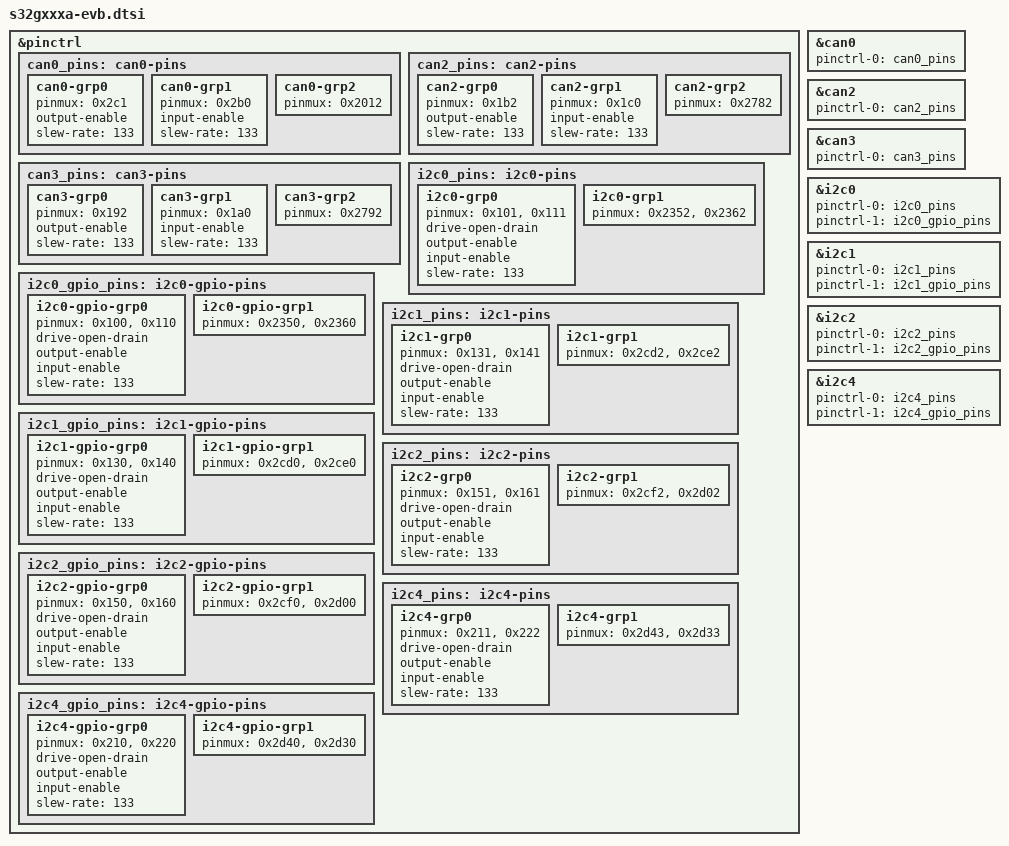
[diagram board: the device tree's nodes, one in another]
// SPDX-License-Identifier: (GPL-2.0+ OR BSD-3-Clause)
/*
 * Copyright 2024 NXP
 *
 * Authors: Ciprian Marian Costea <ciprianmarian.costea@oss.nxp.com>
 *          Ghennadi Procopciuc <ghennadi.procopciuc@oss.nxp.com>
 *          Larisa Grigore <larisa.grigore@nxp.com>
 */

&pinctrl {
	can0_pins: can0-pins {
		can0-grp0 {
			pinmux = <0x2c1>;
			output-enable;
			slew-rate = <133>;
		};

		can0-grp1 {
			pinmux = <0x2b0>;
			input-enable;
			slew-rate = <133>;
		};

		can0-grp2 {
			pinmux = <0x2012>;
		};
	};

	can2_pins: can2-pins {
		can2-grp0 {
			pinmux = <0x1b2>;
			output-enable;
			slew-rate = <133>;
		};

		can2-grp1 {
			pinmux = <0x1c0>;
			input-enable;
			slew-rate = <133>;
		};

		can2-grp2 {
			pinmux = <0x2782>;
		};
	};

	can3_pins: can3-pins {
		can3-grp0 {
			pinmux = <0x192>;
			output-enable;
			slew-rate = <133>;
		};

		can3-grp1 {
			pinmux = <0x1a0>;
			input-enable;
			slew-rate = <133>;
		};

		can3-grp2 {
			pinmux = <0x2792>;
		};
	};

	i2c0_pins: i2c0-pins {
		i2c0-grp0 {
			pinmux = <0x101>, <0x111>;
			drive-open-drain;
			output-enable;
			input-enable;
			slew-rate = <133>;
		};

		i2c0-grp1 {
			pinmux = <0x2352>, <0x2362>;
		};
	};

	i2c0_gpio_pins: i2c0-gpio-pins {
		i2c0-gpio-grp0 {
			pinmux = <0x100>, <0x110>;
			drive-open-drain;
			output-enable;
			input-enable;
			slew-rate = <133>;
		};

		i2c0-gpio-grp1 {
			pinmux = <0x2350>, <0x2360>;
		};
	};

	i2c1_pins: i2c1-pins {
		i2c1-grp0 {
			pinmux = <0x131>, <0x141>;
			drive-open-drain;
			output-enable;
			input-enable;
			slew-rate = <133>;
		};

		i2c1-grp1 {
			pinmux = <0x2cd2>, <0x2ce2>;
		};
	};

	i2c1_gpio_pins: i2c1-gpio-pins {
		i2c1-gpio-grp0 {
			pinmux = <0x130>, <0x140>;
			drive-open-drain;
			output-enable;
			input-enable;
			slew-rate = <133>;
		};

		i2c1-gpio-grp1 {
			pinmux = <0x2cd0>, <0x2ce0>;
		};
	};

	i2c2_pins: i2c2-pins {
		i2c2-grp0 {
			pinmux = <0x151>, <0x161>;
			drive-open-drain;
			output-enable;
			input-enable;
			slew-rate = <133>;
		};

		i2c2-grp1 {
			pinmux = <0x2cf2>, <0x2d02>;
		};
	};

	i2c2_gpio_pins: i2c2-gpio-pins {
		i2c2-gpio-grp0 {
			pinmux = <0x150>, <0x160>;
			drive-open-drain;
			output-enable;
			input-enable;
			slew-rate = <133>;
		};

		i2c2-gpio-grp1 {
			pinmux = <0x2cf0>, <0x2d00>;
		};
	};

	i2c4_pins: i2c4-pins {
		i2c4-grp0 {
			pinmux = <0x211>, <0x222>;
			drive-open-drain;
			output-enable;
			input-enable;
			slew-rate = <133>;
		};

		i2c4-grp1 {
			pinmux = <0x2d43>, <0x2d33>;
		};
	};

	i2c4_gpio_pins: i2c4-gpio-pins {
		i2c4-gpio-grp0 {
			pinmux = <0x210>, <0x220>;
			drive-open-drain;
			output-enable;
			input-enable;
			slew-rate = <133>;
		};

		i2c4-gpio-grp1 {
			pinmux = <0x2d40>, <0x2d30>;
		};
	};
};

&can0 {
	pinctrl-names = "default";
	pinctrl-0 = <&can0_pins>;
	status = "okay";
};

&can2 {
	pinctrl-names = "default";
	pinctrl-0 = <&can2_pins>;
	status = "okay";
};

&can3 {
	pinctrl-names = "default";
	pinctrl-0 = <&can3_pins>;
	status = "okay";
};

&i2c0 {
	pinctrl-names = "default", "gpio";
	pinctrl-0 = <&i2c0_pins>;
	pinctrl-1 = <&i2c0_gpio_pins>;
	status = "okay";
};

&i2c1 {
	pinctrl-names = "default", "gpio";
	pinctrl-0 = <&i2c1_pins>;
	pinctrl-1 = <&i2c1_gpio_pins>;
	status = "okay";
};

&i2c2 {
	pinctrl-names = "default", "gpio";
	pinctrl-0 = <&i2c2_pins>;
	pinctrl-1 = <&i2c2_gpio_pins>;
	status = "okay";
};

&i2c4 {
	pinctrl-names = "default", "gpio";
	pinctrl-0 = <&i2c4_pins>;
	pinctrl-1 = <&i2c4_gpio_pins>;
	status = "okay";
};
